AUTOSAR XML (schema 4-0-3)
standard types defined: uint8, UInt8
package /AUTOSAR_Platform/DataConstrs
  range DC_UInt8: raw 0..255
package /PATAC/MSM/ComponentTypes
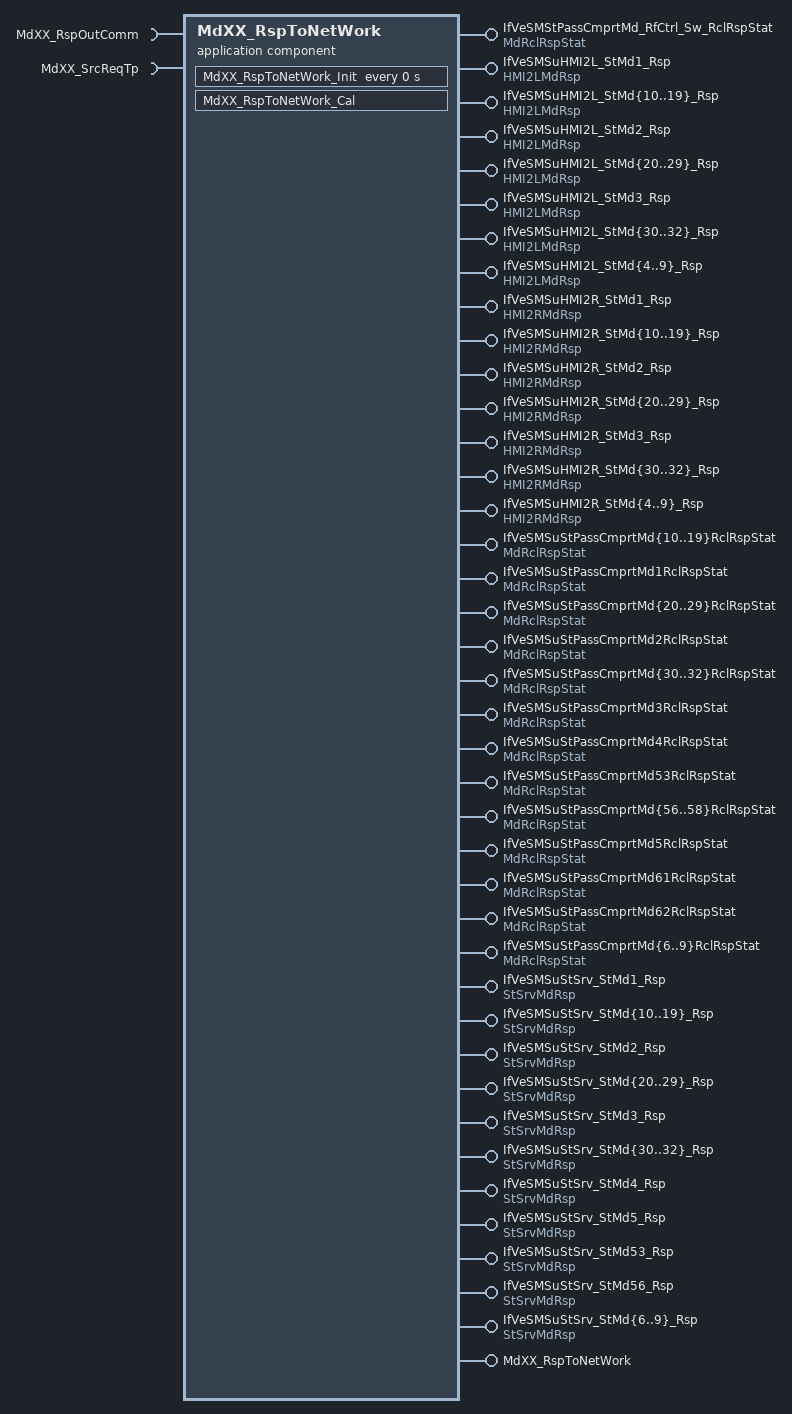
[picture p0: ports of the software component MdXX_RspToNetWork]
  application sw component type MdXX_RspToNetWork
    138 x provide port:
      IfVeSMStPassCmprtMd_RfCtrl_Sw_RclRspStat: nonqueued-sender-com-spec{data-element=MdRclRspStat/Val, init-value=0}, provided-interface=MdRclRspStat
      IfVeSMSuHMI2L_StMd1_Rsp: nonqueued-sender-com-spec{data-element=HMI2LMdRsp/Val, init-value=0}, provided-interface=HMI2LMdRsp
      IfVeSMSuHMI2L_StMd{10..19}_Rsp: nonqueued-sender-com-spec{data-element=HMI2LMdRsp/Val, init-value=0}, provided-interface=HMI2LMdRsp
      IfVeSMSuHMI2L_StMd2_Rsp: nonqueued-sender-com-spec{data-element=HMI2LMdRsp/Val, init-value=0}, provided-interface=HMI2LMdRsp
      IfVeSMSuHMI2L_StMd{20..29}_Rsp: nonqueued-sender-com-spec{data-element=HMI2LMdRsp/Val, init-value=0}, provided-interface=HMI2LMdRsp
      IfVeSMSuHMI2L_StMd3_Rsp: nonqueued-sender-com-spec{data-element=HMI2LMdRsp/Val, init-value=0}, provided-interface=HMI2LMdRsp
      IfVeSMSuHMI2L_StMd{30..32}_Rsp: nonqueued-sender-com-spec{data-element=HMI2LMdRsp/Val, init-value=0}, provided-interface=HMI2LMdRsp
      IfVeSMSuHMI2L_StMd{4..9}_Rsp: nonqueued-sender-com-spec{data-element=HMI2LMdRsp/Val, init-value=0}, provided-interface=HMI2LMdRsp
      IfVeSMSuHMI2R_StMd1_Rsp: nonqueued-sender-com-spec{data-element=HMI2RMdRsp/Val, init-value=0}, provided-interface=HMI2RMdRsp
      IfVeSMSuHMI2R_StMd{10..19}_Rsp: nonqueued-sender-com-spec{data-element=HMI2RMdRsp/Val, init-value=0}, provided-interface=HMI2RMdRsp
      IfVeSMSuHMI2R_StMd2_Rsp: nonqueued-sender-com-spec{data-element=HMI2RMdRsp/Val, init-value=0}, provided-interface=HMI2RMdRsp
      IfVeSMSuHMI2R_StMd{20..29}_Rsp: nonqueued-sender-com-spec{data-element=HMI2RMdRsp/Val, init-value=0}, provided-interface=HMI2RMdRsp
      IfVeSMSuHMI2R_StMd3_Rsp: nonqueued-sender-com-spec{data-element=HMI2RMdRsp/Val, init-value=0}, provided-interface=HMI2RMdRsp
      IfVeSMSuHMI2R_StMd{30..32}_Rsp: nonqueued-sender-com-spec{data-element=HMI2RMdRsp/Val, init-value=0}, provided-interface=HMI2RMdRsp
      IfVeSMSuHMI2R_StMd{4..9}_Rsp: nonqueued-sender-com-spec{data-element=HMI2RMdRsp/Val, init-value=0}, provided-interface=HMI2RMdRsp
      IfVeSMSuStPassCmprtMd{10..19}RclRspStat: nonqueued-sender-com-spec{data-element=MdRclRspStat/Val, init-value=0}, provided-interface=MdRclRspStat
      IfVeSMSuStPassCmprtMd1RclRspStat: nonqueued-sender-com-spec{data-element=MdRclRspStat/Val, init-value=0}, provided-interface=MdRclRspStat
      IfVeSMSuStPassCmprtMd{20..29}RclRspStat: nonqueued-sender-com-spec{data-element=MdRclRspStat/Val, init-value=0}, provided-interface=MdRclRspStat
      IfVeSMSuStPassCmprtMd2RclRspStat: nonqueued-sender-com-spec{data-element=MdRclRspStat/Val, init-value=0}, provided-interface=MdRclRspStat
      IfVeSMSuStPassCmprtMd{30..32}RclRspStat: nonqueued-sender-com-spec{data-element=MdRclRspStat/Val, init-value=0}, provided-interface=MdRclRspStat
      IfVeSMSuStPassCmprtMd3RclRspStat: nonqueued-sender-com-spec{data-element=MdRclRspStat/Val, init-value=0}, provided-interface=MdRclRspStat
      IfVeSMSuStPassCmprtMd4RclRspStat: nonqueued-sender-com-spec{data-element=MdRclRspStat/Val, init-value=0}, provided-interface=MdRclRspStat
      IfVeSMSuStPassCmprtMd53RclRspStat: nonqueued-sender-com-spec{data-element=MdRclRspStat/Val, init-value=0}, provided-interface=MdRclRspStat
      IfVeSMSuStPassCmprtMd{56..58}RclRspStat: nonqueued-sender-com-spec{data-element=MdRclRspStat/Val, init-value=0}, provided-interface=MdRclRspStat
      IfVeSMSuStPassCmprtMd5RclRspStat: nonqueued-sender-com-spec{data-element=MdRclRspStat/Val, init-value=0}, provided-interface=MdRclRspStat
      IfVeSMSuStPassCmprtMd61RclRspStat: nonqueued-sender-com-spec{data-element=MdRclRspStat/Val, init-value=0}, provided-interface=MdRclRspStat
      IfVeSMSuStPassCmprtMd62RclRspStat: nonqueued-sender-com-spec{data-element=MdRclRspStat/Val, init-value=0}, provided-interface=MdRclRspStat
      IfVeSMSuStPassCmprtMd{6..9}RclRspStat: nonqueued-sender-com-spec{data-element=MdRclRspStat/Val, init-value=0}, provided-interface=MdRclRspStat
      IfVeSMSuStSrv_StMd1_Rsp: nonqueued-sender-com-spec{data-element=StSrvMdRsp/Val, init-value=0}, provided-interface=StSrvMdRsp
      IfVeSMSuStSrv_StMd{10..19}_Rsp: nonqueued-sender-com-spec{data-element=StSrvMdRsp/Val, init-value=0}, provided-interface=StSrvMdRsp
      IfVeSMSuStSrv_StMd2_Rsp: nonqueued-sender-com-spec{data-element=StSrvMdRsp/Val, init-value=0}, provided-interface=StSrvMdRsp
      IfVeSMSuStSrv_StMd{20..29}_Rsp: nonqueued-sender-com-spec{data-element=StSrvMdRsp/Val, init-value=0}, provided-interface=StSrvMdRsp
      IfVeSMSuStSrv_StMd3_Rsp: nonqueued-sender-com-spec{data-element=StSrvMdRsp/Val, init-value=0}, provided-interface=StSrvMdRsp
      IfVeSMSuStSrv_StMd{30..32}_Rsp: nonqueued-sender-com-spec{data-element=StSrvMdRsp/Val, init-value=0}, provided-interface=StSrvMdRsp
      IfVeSMSuStSrv_StMd4_Rsp: nonqueued-sender-com-spec{data-element=StSrvMdRsp/Val, init-value=0}, provided-interface=StSrvMdRsp
      IfVeSMSuStSrv_StMd5_Rsp: nonqueued-sender-com-spec{data-element=StSrvMdRsp/Val, init-value=0}, provided-interface=StSrvMdRsp
      IfVeSMSuStSrv_StMd53_Rsp: nonqueued-sender-com-spec{data-element=StSrvMdRsp/Val, init-value=0}, provided-interface=StSrvMdRsp
      IfVeSMSuStSrv_StMd56_Rsp: nonqueued-sender-com-spec{data-element=StSrvMdRsp/Val, init-value=0}, provided-interface=StSrvMdRsp
      IfVeSMSuStSrv_StMd{6..9}_Rsp: nonqueued-sender-com-spec{data-element=StSrvMdRsp/Val, init-value=0}, provided-interface=StSrvMdRsp
      MdXX_RspToNetWork: server-com-spec{operation=Cal, queue-length=1}, provided-interface=MdXX_RspToNetWork
    require port MdXX_RspOutComm: required-interface=MdXX_RspOutComm
      required-com-specs:
        data-element=Md1_RspOutComm, filter=data-filter-type=ALWAYS, init-value=0
        data-element=Md{10..19}_RspOutComm, filter=data-filter-type=ALWAYS, init-value=0
        data-element=Md2_RspOutComm, filter=data-filter-type=ALWAYS, init-value=0
        data-element=Md{20..29}_RspOutComm, filter=data-filter-type=ALWAYS, init-value=0
        data-element=Md3_RspOutComm, filter=data-filter-type=ALWAYS, init-value=0
        data-element=Md{30..32}_RspOutComm, filter=data-filter-type=ALWAYS, init-value=0
        data-element=Md{4..9}_RspOutComm, filter=data-filter-type=ALWAYS, init-value=0
    require port MdXX_SrcReqTp: required-interface=MdXX_SrcReqTp
      required-com-specs:
        data-element=Md1_SrcTp, filter=data-filter-type=ALWAYS, init-value=0
        data-element=Md{10..19}_SrcTp, filter=data-filter-type=ALWAYS, init-value=0
        data-element=Md2_SrcTp, filter=data-filter-type=ALWAYS, init-value=0
        data-element=Md{20..29}_SrcTp, filter=data-filter-type=ALWAYS, init-value=0
        data-element=Md3_SrcTp, filter=data-filter-type=ALWAYS, init-value=0
        data-element=Md{30..32}_SrcTp, filter=data-filter-type=ALWAYS, init-value=0
        data-element=Md{4..9}_SrcTp, filter=data-filter-type=ALWAYS, init-value=0
    behavior MdXX_RspToNetWork_InternalBehavior
      operation invoked event OIT_MdXX_RspToNetWork_Cal_MdXX_RspToNetWork_Cal: start-on-event=MdXX_RspToNetWork_Cal, operation=MdXX_RspToNetWork.Cal
      timing event MdXX_RspToNetWork_InitEvent: start-on-event=MdXX_RspToNetWork_Init, period=0
      runnable MdXX_RspToNetWork_Cal
        data-receive-point-by-arguments:
          64 x access:
            REC_MdXX_RspOutComm_Md1_RspOutComm: accessed-variable=MdXX_RspOutComm.Md1_RspOutComm
            REC_MdXX_RspOutComm_Md{10..19}_RspOutComm: accessed-variable=MdXX_RspOutComm.Md{10..19}_RspOutComm
            REC_MdXX_RspOutComm_Md2_RspOutComm: accessed-variable=MdXX_RspOutComm.Md2_RspOutComm
            REC_MdXX_RspOutComm_Md{20..29}_RspOutComm: accessed-variable=MdXX_RspOutComm.Md{20..29}_RspOutComm
            REC_MdXX_RspOutComm_Md3_RspOutComm: accessed-variable=MdXX_RspOutComm.Md3_RspOutComm
            REC_MdXX_RspOutComm_Md{30..32}_RspOutComm: accessed-variable=MdXX_RspOutComm.Md{30..32}_RspOutComm
            REC_MdXX_RspOutComm_Md{4..9}_RspOutComm: accessed-variable=MdXX_RspOutComm.Md{4..9}_RspOutComm
            REC_MdXX_SrcReqTp_Md1_SrcTp: accessed-variable=MdXX_SrcReqTp.Md1_SrcTp
            REC_MdXX_SrcReqTp_Md{10..19}_SrcTp: accessed-variable=MdXX_SrcReqTp.Md{10..19}_SrcTp
            REC_MdXX_SrcReqTp_Md2_SrcTp: accessed-variable=MdXX_SrcReqTp.Md2_SrcTp
            REC_MdXX_SrcReqTp_Md{20..29}_SrcTp: accessed-variable=MdXX_SrcReqTp.Md{20..29}_SrcTp
            REC_MdXX_SrcReqTp_Md3_SrcTp: accessed-variable=MdXX_SrcReqTp.Md3_SrcTp
            REC_MdXX_SrcReqTp_Md{30..32}_SrcTp: accessed-variable=MdXX_SrcReqTp.Md{30..32}_SrcTp
            REC_MdXX_SrcReqTp_Md{4..9}_SrcTp: accessed-variable=MdXX_SrcReqTp.Md{4..9}_SrcTp
        data-send-points:
          137 x access:
            SEND_IfVeSMStPassCmprtMd_RfCtrl_Sw_RclRspStat_Val: accessed-variable=IfVeSMStPassCmprtMd_RfCtrl_Sw_RclRspStat.Val
            SEND_IfVeSMSuHMI2L_StMd1_Rsp_Val: accessed-variable=IfVeSMSuHMI2L_StMd1_Rsp.Val
            SEND_IfVeSMSuHMI2L_StMd{10..19}_Rsp_Val: accessed-variable=IfVeSMSuHMI2L_StMd{10..19}_Rsp.Val
            SEND_IfVeSMSuHMI2L_StMd2_Rsp_Val: accessed-variable=IfVeSMSuHMI2L_StMd2_Rsp.Val
            SEND_IfVeSMSuHMI2L_StMd{20..29}_Rsp_Val: accessed-variable=IfVeSMSuHMI2L_StMd{20..29}_Rsp.Val
            SEND_IfVeSMSuHMI2L_StMd3_Rsp_Val: accessed-variable=IfVeSMSuHMI2L_StMd3_Rsp.Val
            SEND_IfVeSMSuHMI2L_StMd{30..32}_Rsp_Val: accessed-variable=IfVeSMSuHMI2L_StMd{30..32}_Rsp.Val
            SEND_IfVeSMSuHMI2L_StMd{4..9}_Rsp_Val: accessed-variable=IfVeSMSuHMI2L_StMd{4..9}_Rsp.Val
            SEND_IfVeSMSuHMI2R_StMd1_Rsp_Val: accessed-variable=IfVeSMSuHMI2R_StMd1_Rsp.Val
            SEND_IfVeSMSuHMI2R_StMd{10..19}_Rsp_Val: accessed-variable=IfVeSMSuHMI2R_StMd{10..19}_Rsp.Val
            SEND_IfVeSMSuHMI2R_StMd2_Rsp_Val: accessed-variable=IfVeSMSuHMI2R_StMd2_Rsp.Val
            SEND_IfVeSMSuHMI2R_StMd{20..29}_Rsp_Val: accessed-variable=IfVeSMSuHMI2R_StMd{20..29}_Rsp.Val
            SEND_IfVeSMSuHMI2R_StMd3_Rsp_Val: accessed-variable=IfVeSMSuHMI2R_StMd3_Rsp.Val
            SEND_IfVeSMSuHMI2R_StMd{30..32}_Rsp_Val: accessed-variable=IfVeSMSuHMI2R_StMd{30..32}_Rsp.Val
            SEND_IfVeSMSuHMI2R_StMd{4..9}_Rsp_Val: accessed-variable=IfVeSMSuHMI2R_StMd{4..9}_Rsp.Val
            SEND_IfVeSMSuStPassCmprtMd{10..19}RclRspStat_Val: accessed-variable=IfVeSMSuStPassCmprtMd{10..19}RclRspStat.Val
            SEND_IfVeSMSuStPassCmprtMd1RclRspStat_Val: accessed-variable=IfVeSMSuStPassCmprtMd1RclRspStat.Val
            SEND_IfVeSMSuStPassCmprtMd{20..29}RclRspStat_Val: accessed-variable=IfVeSMSuStPassCmprtMd{20..29}RclRspStat.Val
            SEND_IfVeSMSuStPassCmprtMd2RclRspStat_Val: accessed-variable=IfVeSMSuStPassCmprtMd2RclRspStat.Val
            SEND_IfVeSMSuStPassCmprtMd{30..32}RclRspStat_Val: accessed-variable=IfVeSMSuStPassCmprtMd{30..32}RclRspStat.Val
            SEND_IfVeSMSuStPassCmprtMd3RclRspStat_Val: accessed-variable=IfVeSMSuStPassCmprtMd3RclRspStat.Val
            SEND_IfVeSMSuStPassCmprtMd4RclRspStat_Val: accessed-variable=IfVeSMSuStPassCmprtMd4RclRspStat.Val
            SEND_IfVeSMSuStPassCmprtMd53RclRspStat_Val: accessed-variable=IfVeSMSuStPassCmprtMd53RclRspStat.Val
            SEND_IfVeSMSuStPassCmprtMd{56..58}RclRspStat_Val: accessed-variable=IfVeSMSuStPassCmprtMd{56..58}RclRspStat.Val
            SEND_IfVeSMSuStPassCmprtMd5RclRspStat_Val: accessed-variable=IfVeSMSuStPassCmprtMd5RclRspStat.Val
            SEND_IfVeSMSuStPassCmprtMd61RclRspStat_Val: accessed-variable=IfVeSMSuStPassCmprtMd61RclRspStat.Val
            SEND_IfVeSMSuStPassCmprtMd62RclRspStat_Val: accessed-variable=IfVeSMSuStPassCmprtMd62RclRspStat.Val
            SEND_IfVeSMSuStPassCmprtMd{6..9}RclRspStat_Val: accessed-variable=IfVeSMSuStPassCmprtMd{6..9}RclRspStat.Val
            SEND_IfVeSMSuStSrv_StMd1_Rsp_Val: accessed-variable=IfVeSMSuStSrv_StMd1_Rsp.Val
            SEND_IfVeSMSuStSrv_StMd{10..19}_Rsp_Val: accessed-variable=IfVeSMSuStSrv_StMd{10..19}_Rsp.Val
            SEND_IfVeSMSuStSrv_StMd2_Rsp_Val: accessed-variable=IfVeSMSuStSrv_StMd2_Rsp.Val
            SEND_IfVeSMSuStSrv_StMd{20..29}_Rsp_Val: accessed-variable=IfVeSMSuStSrv_StMd{20..29}_Rsp.Val
            SEND_IfVeSMSuStSrv_StMd3_Rsp_Val: accessed-variable=IfVeSMSuStSrv_StMd3_Rsp.Val
            SEND_IfVeSMSuStSrv_StMd{30..32}_Rsp_Val: accessed-variable=IfVeSMSuStSrv_StMd{30..32}_Rsp.Val
            SEND_IfVeSMSuStSrv_StMd4_Rsp_Val: accessed-variable=IfVeSMSuStSrv_StMd4_Rsp.Val
            SEND_IfVeSMSuStSrv_StMd5_Rsp_Val: accessed-variable=IfVeSMSuStSrv_StMd5_Rsp.Val
            SEND_IfVeSMSuStSrv_StMd53_Rsp_Val: accessed-variable=IfVeSMSuStSrv_StMd53_Rsp.Val
            SEND_IfVeSMSuStSrv_StMd56_Rsp_Val: accessed-variable=IfVeSMSuStSrv_StMd56_Rsp.Val
            SEND_IfVeSMSuStSrv_StMd{6..9}_Rsp_Val: accessed-variable=IfVeSMSuStSrv_StMd{6..9}_Rsp.Val
      runnable MdXX_RspToNetWork_Init
  swc implementation MdXX_RspToNetWork_Implementation: behavior=MdXX_RspToNetWork_InternalBehavior
    code-descriptors:
      code Default: artifact-descriptors=autosar-engineering-object={short-label=Default, category=SWSRC}
package /PATAC/MSM/ModeAdjust/DataType
  impl type SrcReqTp1: category=VALUE, base-type=UInt8, sw-calibration-access=READ-ONLY, compu {0=SrcReqTp_None, 1=SrcReqTp_Local, 2=SrcReqTp_HMI2L, 3=SrcReqTp_HMI2R, 4=SrcReqTp_HMI, 5=SrcReqTp_Remote, 6=SrcReqTp_SRS}, type-emitter=RTE
package /PATAC/MSM/ModeAdjust/PortInterface
  client server interface MdXX_RspToNetWork
    operation Cal
  6 x sender receiver interface:
    HMI2LMdRsp: invalidation-policy{data-element=HMI2LMdRsp/Val, handle-invalid=DONT-INVALIDATE}
      data Val: type=UInt8
    HMI2RMdRsp: invalidation-policy{data-element=HMI2RMdRsp/Val, handle-invalid=DONT-INVALIDATE}
      data Val: type=UInt8
    MdRclRspStat: invalidation-policy{data-element=MdRclRspStat/Val, handle-invalid=DONT-INVALIDATE}
      data Val: type=UInt8
    MdXX_RspOutComm
      32 x data, all with type=UInt8:
        Md1_RspOutComm
        Md{10..19}_RspOutComm
        Md2_RspOutComm
        Md{20..29}_RspOutComm
        Md3_RspOutComm
        Md{30..32}_RspOutComm
        Md{4..9}_RspOutComm
      invalidation-policys:
        data-element=Md1_RspOutComm, handle-invalid=DONT-INVALIDATE
        data-element=Md{10..19}_RspOutComm, handle-invalid=DONT-INVALIDATE
        data-element=Md2_RspOutComm, handle-invalid=DONT-INVALIDATE
        data-element=Md{20..29}_RspOutComm, handle-invalid=DONT-INVALIDATE
        data-element=Md3_RspOutComm, handle-invalid=DONT-INVALIDATE
        data-element=Md{30..32}_RspOutComm, handle-invalid=DONT-INVALIDATE
        data-element=Md{4..9}_RspOutComm, handle-invalid=DONT-INVALIDATE
    MdXX_SrcReqTp
      32 x data, all with type=SrcReqTp1:
        Md1_SrcTp
        Md{10..19}_SrcTp
        Md2_SrcTp
        Md{20..29}_SrcTp
        Md3_SrcTp
        Md{30..32}_SrcTp
        Md{4..9}_SrcTp
      invalidation-policys:
        data-element=Md1_SrcTp, handle-invalid=DONT-INVALIDATE
        data-element=Md{10..19}_SrcTp, handle-invalid=DONT-INVALIDATE
        data-element=Md2_SrcTp, handle-invalid=DONT-INVALIDATE
        data-element=Md{20..29}_SrcTp, handle-invalid=DONT-INVALIDATE
        data-element=Md3_SrcTp, handle-invalid=DONT-INVALIDATE
        data-element=Md{30..32}_SrcTp, handle-invalid=DONT-INVALIDATE
        data-element=Md{4..9}_SrcTp, handle-invalid=DONT-INVALIDATE
    StSrvMdRsp: invalidation-policy{data-element=StSrvMdRsp/Val, handle-invalid=DONT-INVALIDATE}
      data Val: type=UInt8
